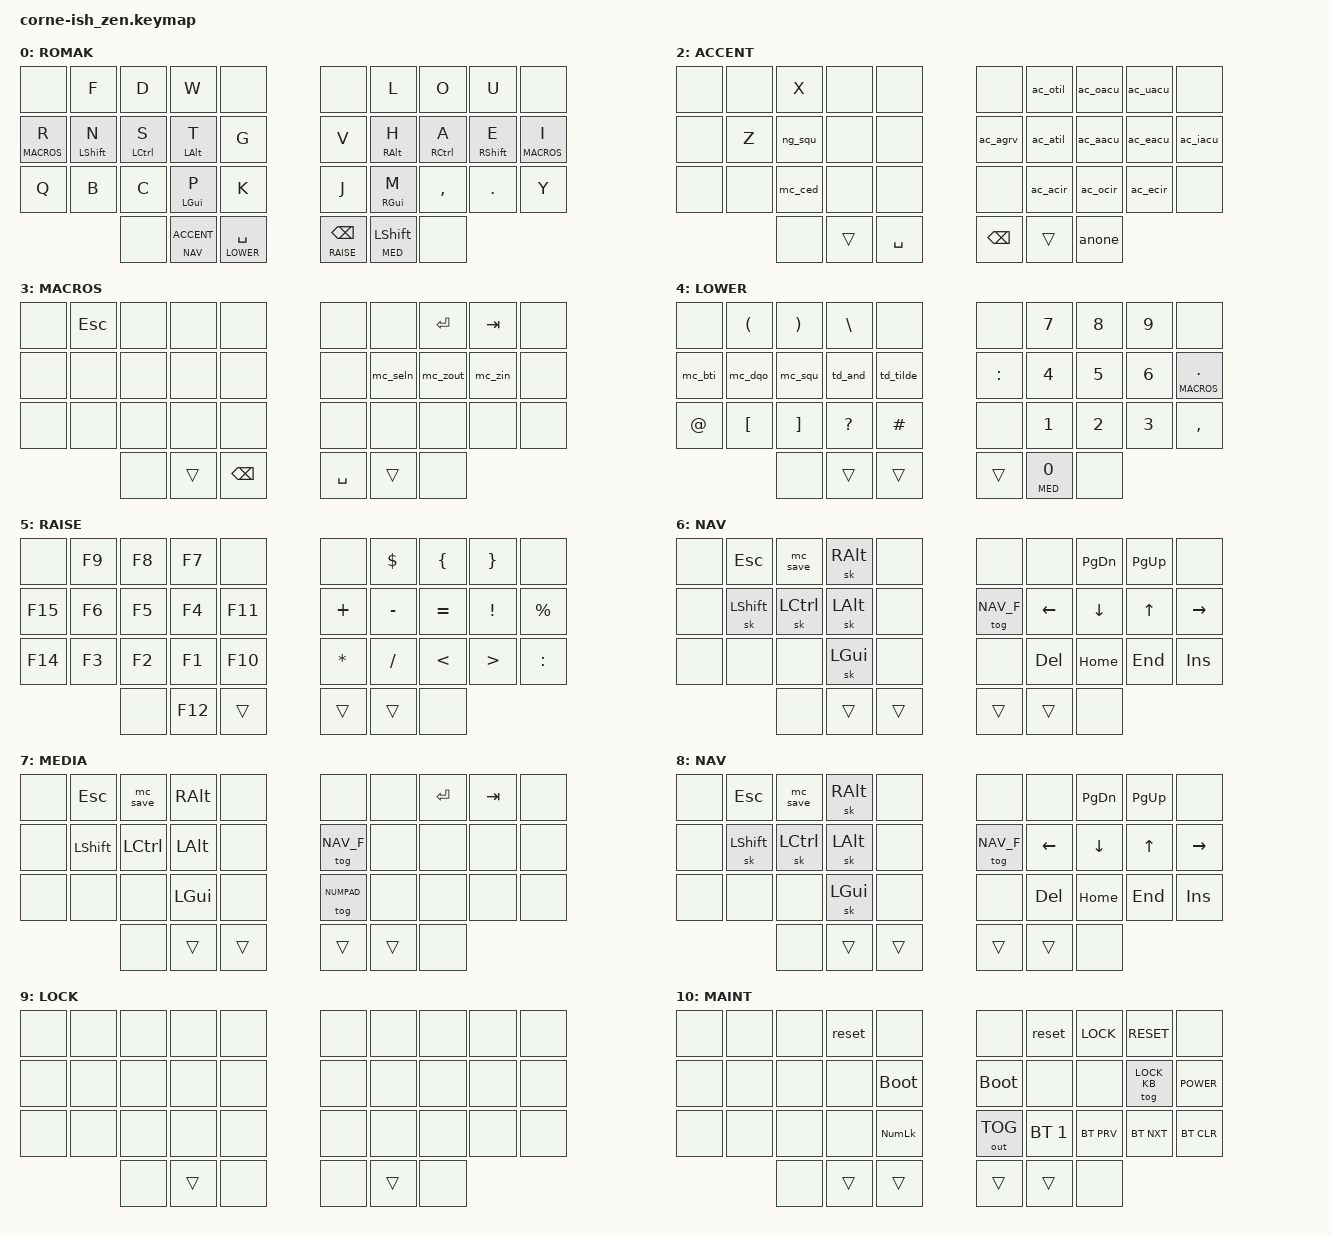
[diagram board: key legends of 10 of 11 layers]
/*
*
* Copyright (c) 2022 Rafael Romão
* SPDX-License-Identifier: MIT
*
*/

#include <behaviors.dtsi>
#include <dt-bindings/zmk/keys.h>
#include <dt-bindings/zmk/bt.h>

#define ROMAK 0
#define NUMPAD 1
#define ACCENT 2
#define MACROS 3
#define LOWER 4
#define RAISE 5
#define NAV_F 6
#define MED 7
#define NAV 8
#define LOCK_KB 9
#define MAINT 10

&sl {
    release-after-ms = <2000>;
};

&sk {
    release-after-ms = <2000>;
};

/ {
    hold-taps {
        msl: layer-tap-with-stick-layer {
            compatible = "zmk,behavior-hold-tap";
            label = "layer-tap-with-stick-layer";
            #binding-cells = <2>;
            flavor = "tap-preferred";
            tapping-term-ms = <175>;
            quick-tap-ms = <0>;
            layer-tap-with-stick-layer;
            bindings = <&mo>, <&sl>;
        };
        msk: layer-tap-with-stick-key {
            compatible = "zmk,behavior-hold-tap";
            label = "layer-tap-with-stick-key";
            #binding-cells = <2>;
            flavor = "tap-preferred";
            tapping-term-ms = <175>;
            quick-tap-ms = <0>;
            layer-tap-with-stick-key;
            bindings = <&mo>, <&sk>;
        };
    };
};

/ {
    macros {
        mc_save: mc_save {
            label = "Save";
            compatible = "zmk,behavior-macro";
            #binding-cells = <0>;
            bindings
                = <&macro_press &kp LCMD>
                , <&macro_tap &kp S>
                , <&macro_release &kp LCMD>
                ;
        };
        mc_seln: mc_seln {
            label = "Select Line";
            compatible = "zmk,behavior-macro";
            #binding-cells = <0>;
            bindings
                = <&macro_tap &kp HOME>
                , <&macro_press &kp LSHFT>
                , <&macro_tap &kp END>
                , <&macro_release &kp LSHFT>
                ;
        };
        mc_zout: mc_zout {
            label = "Zoom Out";
            compatible = "zmk,behavior-macro";
            #binding-cells = <0>;
            bindings
                = <&macro_press &kp LGUI>
                , <&macro_tap &kp MINUS>
                , <&macro_release &kp LGUI>
                ;
        };
        mc_zin: mc_zin {
            label = "Zoom In";
            compatible = "zmk,behavior-macro";
            #binding-cells = <0>;
            bindings
                = <&macro_press &kp LGUI>
                , <&macro_tap &kp PLUS>
                , <&macro_release &kp LGUI>
                ;
        };
    };
};

/ {
    accents {
        ac_agrv: ac_agrv {
            label = "à";
            compatible = "zmk,behavior-macro";
            #binding-cells = <0>;
            bindings = <&macro_tap &kp GRAVE &kp A>;
        };
        ac_acir: ac_acir {
            label = "â";
            compatible = "zmk,behavior-macro";
            #binding-cells = <0>;
            bindings = <&macro_tap &kp CARET &kp A>;
        };
        ac_aacu: ac_aacu {
            label = "á";
            compatible = "zmk,behavior-macro";
            #binding-cells = <0>;
            bindings = <&macro_tap &kp SINGLE_QUOTE &kp A>;
        };
        ac_atil: ac_atil {
            label = "ã";
            compatible = "zmk,behavior-macro";
            #binding-cells = <0>;
            bindings = <&macro_tap &kp TILDE &kp A>;
        };
        ac_eacu: ac_eacu {
            label = "é";
            compatible = "zmk,behavior-macro";
            #binding-cells = <0>;
            bindings = <&macro_tap &kp SINGLE_QUOTE &kp E>;
        };
        ac_ecir: ac_ecir {
            label = "ê";
            compatible = "zmk,behavior-macro";
            #binding-cells = <0>;
            bindings = <&macro_tap &kp CARET &kp E>;
        };
        ac_oacu: ac_oacu {
            label = "ó";
            compatible = "zmk,behavior-macro";
            #binding-cells = <0>;
            bindings = <&macro_tap &kp SINGLE_QUOTE &kp O>;
        };
        ac_ocir: ac_ocir {
            label = "ô";
            compatible = "zmk,behavior-macro";
            #binding-cells = <0>;
            bindings = <&macro_tap &kp CARET &kp O>;
        };
        ac_otil: ac_otil {
            label = "õ";
            compatible = "zmk,behavior-macro";
            #binding-cells = <0>;
            bindings = <&macro_tap &kp TILDE &kp O>;
        };
        ac_uacu: ac_uacu {
            label = "ú";
            compatible = "zmk,behavior-macro";
            #binding-cells = <0>;
            bindings = <&macro_tap &kp SINGLE_QUOTE &kp U>;
        };
        ac_iacu: ac_iacu {
            label = "à";
            compatible = "zmk,behavior-macro";
            #binding-cells = <0>;
            bindings = <&macro_tap &kp SINGLE_QUOTE &kp I>;
        };
        ac_accdi: ac_ccdi {
            label = "ç";
            compatible = "zmk,behavior-macro";
            #binding-cells = <0>;
            bindings = <&macro_tap &kp SINGLE_QUOTE &kp C>;
        };
    };
};

/ {
    symbols {
        mc_bti: mc_bti {
            label = "`";
            compatible = "zmk,behavior-macro";
            #binding-cells = <0>;
            bindings = <&macro_tap &kp SQT &kp SPACE>;
        };
        mc_dqo: mc_dqo {
            label = "quot";
            compatible = "zmk,behavior-macro";
            #binding-cells = <0>;
            bindings = <&macro_tap &kp DQT &kp SPACE>;
        };
        mc_sqo: mc_sqo {
            label = "'";
            compatible = "zmk,behavior-macro";
            #binding-cells = <0>;
            bindings = <&macro_tap &kp GRAVE &kp SPACE>;
        };
        mc_tilde: mc_tilde {
            label = "~";
            compatible = "zmk,behavior-macro";
            #binding-cells = <0>;
            bindings = <&macro_tap &kp TILDE &kp AMPS>;
        };
        mc_caret: mc_caret {
            label = "^";
            compatible = "zmk,behavior-macro";
            #binding-cells = <0>;
            bindings = <&macro_tap &kp CARET &kp AMPS>;
        };
        mm_tilde: mm_tilde {
            label = "Dead ~";
            compatible = "zmk,behavior-mod-morph";
            #binding-cells = <0>;
            bindings = <&mc_tild>, <&kp TILDE>;
            mods = <(MOD_LSFT|MOD_RSFT)>;
        };
        mm_caret: mm_caret {
            label = "Dead ^";
            compatible = "zmk,behavior-mod-morph";
            #binding-cells = <0>;
            bindings = <&mc_caret>, <&kp CARET>;
            mods = <(MOD_LSFT|MOD_RSFT)>;
        };
        td_tilde: td_tilde {
            label = "~ ^";
            compatible = "zmk,behavior-tap-dance";
            #binding-cells = <0>;
            tapping-term-ms = <175>;
            bindings = <&mt &mm_caret &mm_tilde>;
        };
        mc_and: mc_and {
            label = "&&";
            compatible = "zmk,behavior-macro";
            #binding-cells = <0>;
            bindings = <&macro_tap &kp AMPS &kp AMPS>;
        };
        mm_and: mm_and {
            label = "&";
            compatible = "zmk,behavior-mod-morph";
            #binding-cells = <0>;
            bindings = <&mc_and>, <&kp AMPS>;
            mods = <(MOD_LSFT|MOD_RSFT)>;
        };
        mc_or: mc_or {
            label = "||";
            compatible = "zmk,behavior-macro";
            #binding-cells = <0>;
            bindings = <&macro_tap &kp PIPE &kp PIPE>;
        };
        mm_or: mm_or {
            label = "|";
            compatible = "zmk,behavior-mod-morph";
            #binding-cells = <0>;
            bindings = <&mc_or>, <&kp PIPE>;
            mods = <(MOD_LSFT|MOD_RSFT)>;
        };
        td_and: td_and {
            label = "&& ||";
            compatible = "zmk,behavior-tap-dance";
            #binding-cells = <0>;
            tapping-term-ms = <175>;
            bindings = <&mt &mm_or &mm_and>;
        };
    };
};

/ {
        keymap {
                compatible = "zmk,keymap";
                default_layer {
                        label = "ROMAK";
                        bindings = <
   &none           &kp F           &kp D           &kp W           &none           &none           &kp L           &kp O           &kp U           &none    
   &lt MACROS R    &mt LSHFT N     &mt LCTRL S     &mt LALT T      &kp G           &kp V           &mt RALT H      &mt RCTRL A     &mt RSHFT E     &lt MACROS I 
   &kp Q           &kp B           &kp C           &mt LGUI P      &kp K           &kp J           &mt RGUI M      &kp COMMA       &kp DOT         &kp Y
                                   &none           &msl NAV ACCENT &lt LOWER SPACE &lt RAISE BSPC  &msk MED LSHFT  &none
                        >;
                };
                numpad_layer {
                        label = "NUMPAD";
                        bindings = <
   &none           &kp F9          &kp F8          &kp F7          &none           &none           &kp N7          &kp N8          &kp N9          &none    
   &kp F15         &mt LSHFT F6    &mt LCTRL F5    &mt LALT F4     &kp F11         &kp COLON       &mt RALT N4     &mt RCTRL N5    &mt RSHFT N6    &lt MACROS DOT 
   &kp F14         &kp F3          &kp F2          &mt F1          &kp LGUI F10    &tog NUMPAD     &mt RGUI N1     &kp N2          &kp N3          &kp COMMA
                                   &none           &msl NAV F12    &trans          &trans          &msk MED N0     &none
                        >;
                };
                accents_layer {
                        label = "ACCENT";
                        bindings = <
   &none           &none           &kp X           &none           &none           &none           &ac_otil        &ac_oacu        &ac_uacu        &none    
   &none           &kp Z           &ng_squ         &none           &none           &ac_agrv        &ac_atil        &ac_aacu        &ac_eacu        &ac_iacu 
   &none           &none           &mc_ced         &none           &none           &none           &ac_acir        &ac_ocir        &ac_ecir        &none
                                   &none           &trans          &kp SPACE       &kp BSPC        &trans          &anone
                        >;
                };
                macros_layer {
                        label = "MACROS";
                        bindings = <
   &none           &kp ESC         &none           &none           &none           &none           &none         &kp ENTER       &kp TAB       &none    
   &none           &none           &none           &none           &none           &none           &mc_seln      &mc_zout        &mc_zin       &none  
   &none           &none           &none           &none           &none           &none           &none         &none           &none         &none 
                                   &none           &trans          &kp BSPC        &kp SPACE       &trans        &none
                        >;
                };
                lower_layer {
                        label = "LOWER";
                        bindings = <
   &none           &kp LPAR        &kp RPAR        &kp BSLH        &none           &none           &kp N7        &kp N8          &kp N9        &none    
   &mc_bti         &mc_dqo         &mc_squ         &td_and         &td_tilde       &kp COLON       &kp N4        &kp N5          &kp N6        &lt MACROS DOT  
   &kp AT          &kp LBKT        &kp RBKT        &kp QMARK       &kp HASH        &none           &kp N1        &kp N2          &kp N3        &kp COMMA 
                                   &none           &trans          &trans          &trans          &msk MED N0   &none
                        >;
                };
                raise_layer {
                        label = "RAISE";
                        bindings = <
   &none           &kp F9          &kp F8          &kp F7          &none           &none           &kp DOLLAR    &kp LBRC        &kp RBRC      &none    
   &kp F15         &kp F6          &kp F5          &kp F4          &kp F11         &kp PLUS        &kp MINUS     &kp EQUAL       &kp EXCL      &kp PERCENT  
   &kp F14         &kp F3          &kp F2          &kp F1          &kp F10         &kp STAR        &kp SLASH     &kp LT          &kp GT        &kp COLON
                                   &none           &kp F12         &trans          &trans          &trans        &none
                        >;
                };
                fixed_navigation_layer {
                        label = "NAV";
                        bindings = <
   &none           &kp ESC         &mc_save        &sk RALT        &none           &none           &none         &kp PAGE_DOWN   &kp PAGE_UP   &none    
   &none           &sk LSHIFT      &sk LCTRL       &sk LALT        &none           &tog NAV_F      &kp LEFT      &kp DOWN        &kp UP        &kp RIGHT
   &none           &none           &none           &sk LGUI        &none           &none           &kp DEL       &kp HOME        &kp END       &kp INS
                                   &none           &trans          &trans          &trans          &trans        &none
                        >;
                };
                media_layer {
                        label = "MEDIA";
                        bindings = <
   &none           &kp ESC         &mc_save        &kp RALT        &none           &none           &none         &kp ENTER       &kp TAB       &none    
   &none           &kp LSHIFT      &kp LCTRL       &kp LALT        &none           &tog NAV_F      &none         &none           &none         &none
   &none           &none           &none           &kp LGUI        &none           &tog NUMPAD     &none         &none           &none         &none 
                                   &none           &trans          &trans          &trans          &trans        &none
                        >;
                };
                navigation_layer {
                        label = "NAV";
                        bindings = <
   &none           &kp ESC         &mc_save        &sk RALT        &none           &none           &none         &kp PAGE_DOWN   &kp PAGE_UP   &none    
   &none           &sk LSHIFT      &sk LCTRL       &sk LALT        &none           &tog NAV_F      &kp LEFT      &kp DOWN        &kp UP        &kp RIGHT
   &none           &none           &none           &sk LGUI        &none           &none           &kp DEL       &kp HOME        &kp END       &kp INS
                                   &none           &trans          &trans          &trans          &trans        &none
                        >;
                };
                lock_layer {
                        label = "LOCK";
                        bindings = <
   &none           &none           &none           &none           &none           &none           &none         &none           &none         &none    
   &none           &none           &none           &none           &none           &none           &none         &none           &none         &none  
   &none           &none           &none           &none           &none           &none           &none         &none           &none         &none 
                                   &none           &trans          &none           &none           &trans        &none
                        >;
                };
                maintenance_layer {
                        label = "MAINT";
                        bindings = <
   &none           &none           &none           &reset          &none           &none           &reset        &kp LOCK        &kp C_RESET   &none    
   &none           &none           &none           &none           &bootloader     &bootloader     &none         &none           &tog LOCK_KB  &kp C_POWER  
   &none           &none           &none           &none           &kp KP_NUMLOCK  &out OUT_TOG    &bt BT_SEL 1  &bt BT_PRV      &bt BT_NXT    &bt BT_CLR 
                                   &none           &trans          &trans          &trans          &trans        &none
                        >;
                };
        };
};
